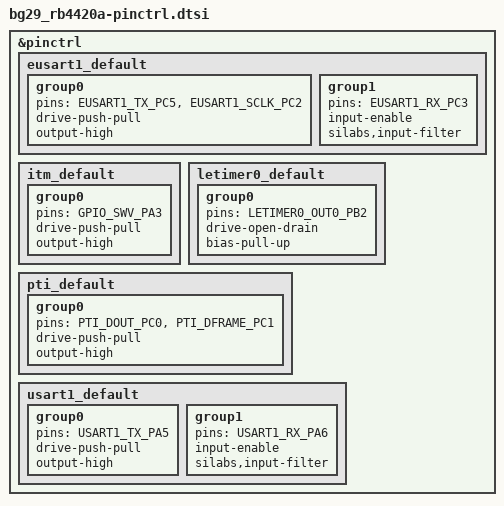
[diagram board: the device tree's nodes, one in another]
/*
 * Copyright (c) 2025 Silicon Laboratories Inc.
 *
 * SPDX-License-Identifier: Apache-2.0
 */

#include <zephyr/dt-bindings/pinctrl/silabs/xg29-pinctrl.h>

&pinctrl {
	eusart1_default: eusart1_default {
		group0 {
			pins = <EUSART1_TX_PC5>, <EUSART1_SCLK_PC2>;
			drive-push-pull;
			output-high;
		};

		group1 {
			pins = <EUSART1_RX_PC3>;
			input-enable;
			silabs,input-filter;
		};
	};

	itm_default: itm_default {
		group0 {
			pins = <GPIO_SWV_PA3>;
			drive-push-pull;
			output-high;
		};
	};

	letimer0_default: letimer0_default {
		group0 {
			pins = <LETIMER0_OUT0_PB2>;
			drive-open-drain;
			bias-pull-up;
		};
	};

	pti_default: pti_default {
		group0 {
			pins = <PTI_DOUT_PC0>, <PTI_DFRAME_PC1>;
			drive-push-pull;
			output-high;
		};
	};

	usart1_default: usart1_default {
		group0 {
			pins = <USART1_TX_PA5>;
			drive-push-pull;
			output-high;
		};

		group1 {
			pins = <USART1_RX_PA6>;
			input-enable;
			silabs,input-filter;
		};
	};
};
